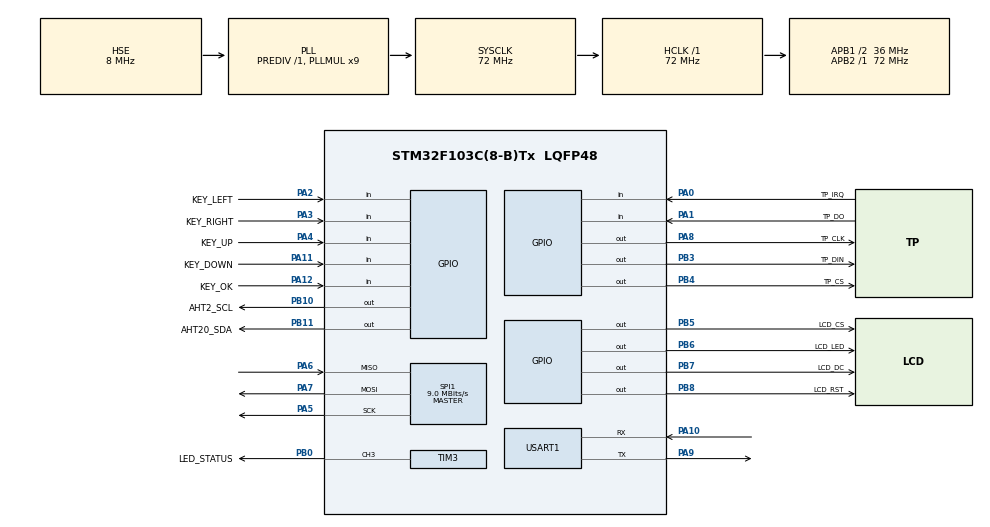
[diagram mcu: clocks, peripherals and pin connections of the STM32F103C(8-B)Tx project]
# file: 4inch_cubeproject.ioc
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Mcu.Family=STM32F1
Mcu.Name=STM32F103C(8-B)Tx
Mcu.Package=LQFP48
NVIC.PriorityGroup=NVIC_PRIORITYGROUP_4
PA0-WKUP.GPIO_Label=TP_IRQ
PA0-WKUP.GPIO_PuPd=GPIO_PULLUP
PA0-WKUP.Signal=GPIO_Input
PA1.GPIO_Label=TP_DO
PA1.GPIO_PuPd=GPIO_PULLUP
PA1.Signal=GPIO_Input
PA10.Mode=Asynchronous
PA10.Signal=USART1_RX
PA11.GPIO_Label=KEY_DOWN
PA11.GPIO_PuPd=GPIO_PULLUP
PA11.Signal=GPIO_Input
PA12.GPIO_Label=KEY_OK
PA12.GPIO_PuPd=GPIO_PULLUP
PA12.Signal=GPIO_Input
PA13.Mode=Serial_Wire
PA13.Signal=SYS_JTMS-SWDIO
PA14.Mode=Serial_Wire
PA14.Signal=SYS_JTCK-SWCLK
PA2.GPIO_Label=KEY_LEFT
PA2.GPIO_PuPd=GPIO_PULLUP
PA2.Signal=GPIO_Input
PA3.GPIO_Label=KEY_RIGHT
PA3.GPIO_PuPd=GPIO_PULLUP
PA3.Signal=GPIO_Input
PA4.GPIO_Label=KEY_UP
PA4.GPIO_PuPd=GPIO_PULLUP
PA4.Signal=GPIO_Input
PA5.Mode=Full_Duplex_Master
PA5.Signal=SPI1_SCK
PA6.Mode=Full_Duplex_Master
PA6.Signal=SPI1_MISO
PA7.Mode=Full_Duplex_Master
PA7.Signal=SPI1_MOSI
PA8.GPIO_Label=TP_CLK
PA8.GPIO_Speed=GPIO_SPEED_FREQ_HIGH
PA8.PinState=GPIO_PIN_RESET
PA8.Signal=GPIO_Output
PA9.Mode=Asynchronous
PA9.Signal=USART1_TX
PB0.GPIO_Label=LED_STATUS
PB0.Signal=S_TIM3_CH3
PB10.GPIO_Label=AHT2_SCL
PB10.GPIO_PuPd=GPIO_PULLUP
PB10.GPIO_Speed=GPIO_SPEED_FREQ_HIGH
PB10.PinState=GPIO_PIN_SET
PB10.Signal=GPIO_Output
PB11.GPIO_Label=AHT20_SDA
PB11.GPIO_PuPd=GPIO_PULLUP
PB11.GPIO_Speed=GPIO_SPEED_FREQ_HIGH
PB11.PinState=GPIO_PIN_SET
PB11.Signal=GPIO_Output
PB3.GPIO_Label=TP_DIN
PB3.PinState=GPIO_PIN_SET
PB3.Signal=GPIO_Output
PB4.GPIO_Label=TP_CS
PB4.PinState=GPIO_PIN_SET
PB4.Signal=GPIO_Output
PB5.GPIO_Label=LCD_CS
PB5.PinState=GPIO_PIN_SET
PB5.Signal=GPIO_Output
PB6.GPIO_Label=LCD_LED
PB6.GPIO_Speed=GPIO_SPEED_FREQ_MEDIUM
PB6.PinState=GPIO_PIN_SET
PB6.Signal=GPIO_Output
PB7.GPIO_Label=LCD_DC
PB7.GPIO_Speed=GPIO_SPEED_FREQ_MEDIUM
PB7.PinState=GPIO_PIN_SET
PB7.Signal=GPIO_Output
PB8.GPIO_Label=LCD_RST
PB8.GPIO_Speed=GPIO_SPEED_FREQ_HIGH
PB8.PinState=GPIO_PIN_SET
PB8.Signal=GPIO_Output
PD0-OSC_IN.Mode=HSE-External-Oscillator
PD0-OSC_IN.Signal=RCC_OSC_IN
PD1-OSC_OUT.Mode=HSE-External-Oscillator
PD1-OSC_OUT.Signal=RCC_OSC_OUT
ProjectManager.HeapSize=0x200
ProjectManager.StackSize=0x400
ProjectManager.TargetToolchain=CMake
RCC.AHBFreq_Value=72000000
RCC.APB1CLKDivider=RCC_HCLK_DIV2
RCC.APB1Freq_Value=36000000
RCC.APB1TimFreq_Value=72000000
RCC.APB2Freq_Value=72000000
RCC.APB2TimFreq_Value=72000000
RCC.HCLKFreq_Value=72000000
RCC.PLLMUL=RCC_PLL_MUL9
RCC.PLLSourceVirtual=RCC_PLLSOURCE_HSE
RCC.SYSCLKFreq_VALUE=72000000
RCC.SYSCLKSource=RCC_SYSCLKSOURCE_PLLCLK
RCC.USBFreq_Value=72000000
SH.S_TIM3_CH3.0=TIM3_CH3,PWM Generation3 CH3
SPI1.BaudRatePrescaler=SPI_BAUDRATEPRESCALER_8
SPI1.CLKPhase=SPI_PHASE_1EDGE
SPI1.CLKPolarity=SPI_POLARITY_LOW
SPI1.CalculateBaudRate=9.0 MBits/s
SPI1.Direction=SPI_DIRECTION_2LINES
SPI1.Mode=SPI_MODE_MASTER
SPI1.VirtualType=VM_MASTER
TIM3.Channel-PWM\ Generation3\ CH3=TIM_CHANNEL_3
TIM3.OCPolarity_3=TIM_OCPOLARITY_LOW
TIM3.Period=999
TIM3.Prescaler=71
USART1.VirtualMode=VM_ASYNC
VP_TIM3_VS_ClockSourceINT.Mode=Internal
board=custom

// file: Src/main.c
/* USER CODE BEGIN Header */
/**
  ******************************************************************************
  * @file           : main.c
  * @brief          : Main program body
  ******************************************************************************
  * @attention
  *
  * Copyright (c) 2026 STMicroelectronics.
  * All rights reserved.
  *
  * This software is licensed under terms that can be found in the LICENSE file
  * in the root directory of this software component.
  * If no LICENSE file comes with this software, it is provided AS-IS.
  *
  ******************************************************************************
  */
/* USER CODE END Header */
#include "main.h"
#include "spi.h"
#include "tim.h"
#include "usart.h"
#include "gpio.h"

/* USER CODE BEGIN Includes */
#include "lcd.h"
#include "aht20.h"
#include "test.h"

/* USER CODE END Includes */

void SystemClock_Config(void);

int main(void)
{

  /* MCU Configuration--------------------------------------------------------*/

  /* Reset of all peripherals, Initializes the Flash interface and the Systick. */
  HAL_Init();

  /* Configure the system clock */
  SystemClock_Config();

  /* Initialize all configured peripherals */
  MX_GPIO_Init();
  MX_SPI1_Init();
  MX_USART1_UART_Init();
  MX_TIM3_Init();
  /* USER CODE BEGIN 2 */
  LCD_Init();
  AHT20_Init();
  main_test();
  /* USER CODE END 2 */

  /* Infinite loop */
  while (1)
  {

    /* USER CODE BEGIN 3 */
    HAL_Delay(1000);
  }
  /* USER CODE END 3 */
}

void SystemClock_Config(void)
{
  RCC_OscInitTypeDef RCC_OscInitStruct = {0};
  RCC_ClkInitTypeDef RCC_ClkInitStruct = {0};

  /** Initializes the RCC Oscillators according to the specified parameters
  * in the RCC_OscInitTypeDef structure.
  */
  RCC_OscInitStruct.OscillatorType = RCC_OSCILLATORTYPE_HSE;
  RCC_OscInitStruct.HSEState = RCC_HSE_ON;
  RCC_OscInitStruct.HSEPredivValue = RCC_HSE_PREDIV_DIV1;
  RCC_OscInitStruct.HSIState = RCC_HSI_ON;
  RCC_OscInitStruct.PLL.PLLState = RCC_PLL_ON;
  RCC_OscInitStruct.PLL.PLLSource = RCC_PLLSOURCE_HSE;
  RCC_OscInitStruct.PLL.PLLMUL = RCC_PLL_MUL9;
  if (HAL_RCC_OscConfig(&RCC_OscInitStruct) != HAL_OK)
  {
    Error_Handler();
  }

  /** Initializes the CPU, AHB and APB buses clocks
  */
  RCC_ClkInitStruct.ClockType = RCC_CLOCKTYPE_HCLK|RCC_CLOCKTYPE_SYSCLK
                              |RCC_CLOCKTYPE_PCLK1|RCC_CLOCKTYPE_PCLK2;
  RCC_ClkInitStruct.SYSCLKSource = RCC_SYSCLKSOURCE_PLLCLK;
  RCC_ClkInitStruct.AHBCLKDivider = RCC_SYSCLK_DIV1;
  RCC_ClkInitStruct.APB1CLKDivider = RCC_HCLK_DIV2;
  RCC_ClkInitStruct.APB2CLKDivider = RCC_HCLK_DIV1;

  if (HAL_RCC_ClockConfig(&RCC_ClkInitStruct, FLASH_LATENCY_2) != HAL_OK)
  {
    Error_Handler();
  }
}

void Error_Handler(void)
{
  __disable_irq();
  while (1)
  {
  }
}
